AUTOSAR XML (schema 00051)
package /Components
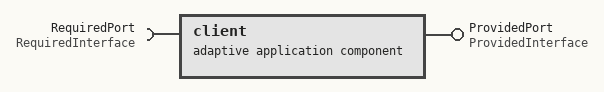
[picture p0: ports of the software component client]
  adaptive application sw component type client
    require port RequiredPort: queued-receiver-com-spec=data-element=In1, required-interface=RequiredInterface
    provide port ProvidedPort: provided-interface=ProvidedInterface
